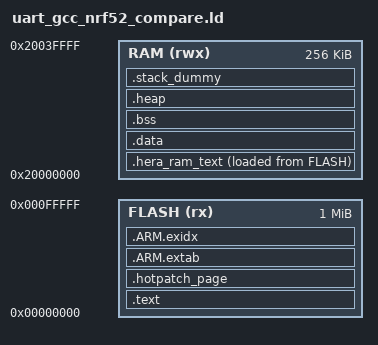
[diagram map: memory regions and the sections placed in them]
/* Linker script for nRF52840 hotpatch experiments.
 *
 * This is a self-contained variant of the Nordic GCC script with explicit
 * nRF52840 FLASH/RAM regions and a dedicated hotpatch section placed directly
 * after .text so patch_slot and fun2 stay adjacent.
 */

OUTPUT_FORMAT ("elf32-littlearm", "elf32-bigarm", "elf32-littlearm")

ENTRY(Reset_Handler)

MEMORY
{
    FLASH (rx)  : ORIGIN = 0x00000000, LENGTH = 0x00100000
    RAM   (rwx) : ORIGIN = 0x20000000, LENGTH = 0x00040000
}

SECTIONS
{
    .text :
    {
        KEEP(*(.isr_vector))
        *(.text*)

        KEEP(*(.init))
        KEEP(*(.fini))

        /* .ctors */
        *crtbegin.o(.ctors)
        *crtbegin?.o(.ctors)
        *(EXCLUDE_FILE(*crtend?.o *crtend.o) .ctors)
        *(SORT(.ctors.*))
        *(.ctors)

        /* .dtors */
        *crtbegin.o(.dtors)
        *crtbegin?.o(.dtors)
        *(EXCLUDE_FILE(*crtend?.o *crtend.o) .dtors)
        *(SORT(.dtors.*))
        *(.dtors)

        *(.rodata*)

        KEEP(*(.eh_frame*))
    } > FLASH

    .hotpatch_page ALIGN(0x1000) :
    {
        __hotpatch_page_start__ = .;
        . = ALIGN(2);
        KEEP(*(.hotpatch_page.slot))
        KEEP(*(.hotpatch_page.entry))
        KEEP(*(.hotpatch_page))
        KEEP(*(.hotpatch_page.*))
        . = ALIGN(4);
        __hotpatch_page_end__ = .;
    } > FLASH

    .ARM.extab :
    {
        *(.ARM.extab* .gnu.linkonce.armextab.*)
    } > FLASH

    __exidx_start = .;
    .ARM.exidx :
    {
        *(.ARM.exidx* .gnu.linkonce.armexidx.*)
    } > FLASH
    __exidx_end = .;

    .hera_ram_text :
    {
        . = ALIGN(4);
        __hera_ram_text_start__ = .;
        KEEP(*(.hera_ram_text))
        KEEP(*(.hera_ram_text.*))
        . = ALIGN(4);
        __hera_ram_text_end__ = .;
    } > RAM AT > FLASH

    __hera_ram_text_load_start__ = LOADADDR(.hera_ram_text);

    . = ALIGN(4);
    __etext = LOADADDR(.hera_ram_text) + SIZEOF(.hera_ram_text);

    .data : AT (__etext)
    {
        __data_start__ = .;
        *(vtable)
        *(.data*)

        . = ALIGN(4);

        /* preinit data */
        PROVIDE_HIDDEN (__preinit_array_start = .);
        KEEP(*(.preinit_array))
        PROVIDE_HIDDEN (__preinit_array_end = .);

        . = ALIGN(4);

        /* init data */
        PROVIDE_HIDDEN (__init_array_start = .);
        KEEP(*(SORT(.init_array.*)))
        KEEP(*(.init_array))
        PROVIDE_HIDDEN (__init_array_end = .);

        . = ALIGN(4);

        /* fini data */
        PROVIDE_HIDDEN (__fini_array_start = .);
        KEEP(*(SORT(.fini_array.*)))
        KEEP(*(.fini_array))
        PROVIDE_HIDDEN (__fini_array_end = .);

        KEEP(*(.jcr*))
        . = ALIGN(4);

        __data_end__ = .;
    } > RAM

    .bss :
    {
        . = ALIGN(4);
        __bss_start__ = .;
        *(.bss*)
        *(COMMON)
        . = ALIGN(4);
        __bss_end__ = .;
    } > RAM

    .heap (COPY):
    {
        __HeapBase = .;
        __end__ = .;
        PROVIDE(end = .);
        KEEP(*(.heap*))
        __HeapLimit = .;
    } > RAM

    .stack_dummy (COPY):
    {
        KEEP(*(.stack*))
    } > RAM

    __StackTop = ORIGIN(RAM) + LENGTH(RAM);
    __StackLimit = __StackTop - SIZEOF(.stack_dummy);
    PROVIDE(__stack = __StackTop);

    ASSERT(__StackLimit >= __HeapLimit, "region RAM overflowed with stack")

    DataInitFlashUsed = __bss_start__ - __data_start__;
    CodeFlashUsed = __etext - ORIGIN(FLASH);
    TotalFlashUsed = CodeFlashUsed + DataInitFlashUsed;
    ASSERT(TotalFlashUsed <= LENGTH(FLASH), "region FLASH overflowed with .data and user data")
}
